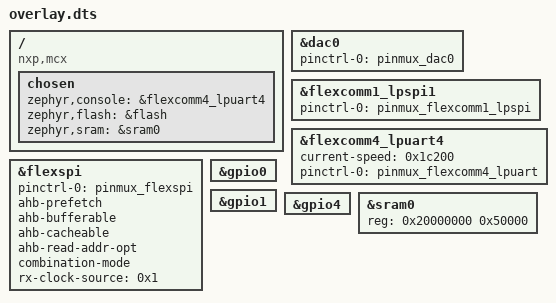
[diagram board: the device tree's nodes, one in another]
/ {
	compatible = "nxp,mcx", "nxp,mcxn947";
	chosen {
		zephyr,console = &flexcomm4_lpuart4;
		zephyr,flash = &flash;
		zephyr,sram = &sram0;
	};
};
&dac0{
	status = "okay";
	pinctrl-0 = < &pinmux_dac0 >;
	pinctrl-names = "default";
};
&flexcomm1_lpspi1{
	status = "okay";
	pinctrl-0 = < &pinmux_flexcomm1_lpspi >;
	pinctrl-names = "default";
};
&flexcomm4_lpuart4{
	status = "okay";
	current-speed = < 0x1c200 >;
	pinctrl-0 = < &pinmux_flexcomm4_lpuart >;
	pinctrl-names = "default";
};
&flexspi{
	status = "okay";
	pinctrl-0 = < &pinmux_flexspi >;
	pinctrl-names = "default";
	ahb-prefetch;
	ahb-bufferable;
	ahb-cacheable;
	ahb-read-addr-opt;
	combination-mode;
	rx-clock-source = < 0x1 >;
};
&gpio0{
	status = "okay";
};
&gpio1{
	status = "okay";
};
&gpio4{
	status = "okay";
};
&sram0{
	reg = < 0x20000000 0x50000 >;
};
